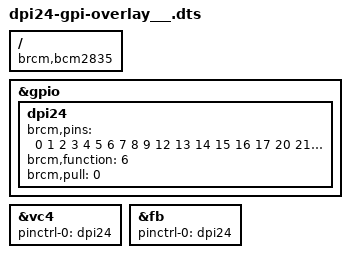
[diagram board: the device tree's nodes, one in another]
/*
 * vc4-kms-v3d-overlay.dts
 */

/dts-v1/;
/plugin/;

#include <dt-bindings/pinctrl/bcm2835.h>

/ {
	compatible = "brcm,bcm2835";

/*	fragment@0 {
		target-path = "/";
		__overlay__ {
			panel: panel {
				compatible = "retroflag_gpi", "simple-panel";
				orientation = <90>;
				
				port {
					panel_in: endpoint {
						remote-endpoint = <&dpi_out>;
					};
				};
			};
		};
	};

	fragment@2 {
		target = <&dpi>;
		__overlay__  {
			status = "okay";

			port {
				dpi_out: endpoint@0 {
					remote-endpoint = <&panel_in>;
				};
			};
		};
	}; */

	fragment@3 {
		target = <&gpio>;
		__overlay__ {
			dpi24: dpi24 {
				brcm,pins = <0 1 2 3 4 5 6 7 8 9
					         12 13 14 15 16 17 20
					         21 22 23 24 25>;
				brcm,function = <6>;
                brcm,pull = <0>;
			};
		};
	};

	fragment@4 {
		target = <&vc4>;
		__overlay__ {
			pinctrl-names = "default";
			pinctrl-0 = <&dpi24>;
		};
	};

	fragment@5 {
		target = <&fb>;
		__overlay__ {
			pinctrl-names = "default";
			pinctrl-0 = <&dpi24>;
		};
	};
};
